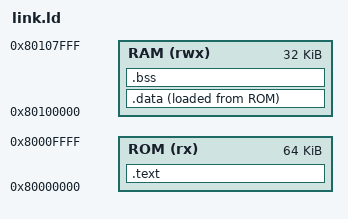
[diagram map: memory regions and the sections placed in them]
/* Memory map consumed by rtl/soc/rv32_nano_soc.sv. */
OUTPUT_ARCH(riscv)
ENTRY(_start)

MEMORY
{
    ROM (rx)  : ORIGIN = 0x80000000, LENGTH = 64K
    RAM (rwx) : ORIGIN = 0x80100000, LENGTH = 32K
}

/* _sp is the top of the dedicated machine-interrupt stack.  The software
 * stacks and .bss are placed below it by the linker. */
_sp = ORIGIN(RAM) + LENGTH(RAM);

SECTIONS
{
    .text : ALIGN(4)
    {
        KEEP(*(.text.startup))
        KEEP(*(.text.entry))
        *(.text .text.*)
        *(.rodata .rodata.*)
        . = ALIGN(4);
        __text_end = .;
    } > ROM

    .data : ALIGN(4)
    {
        __data_start = .;
        *(.data .data.*)
        . = ALIGN(4);
        __data_end = .;
    } > RAM AT > ROM
    __data_load = LOADADDR(.data);

    .bss (NOLOAD) : ALIGN(4)
    {
        __bss_start = .;
        *(.bss .bss.* COMMON)
        . = ALIGN(4);
        __bss_end = .;
    } > RAM

    . = ALIGN(4);
    __image_end = .;

    /DISCARD/ :
    {
        *(.comment)
        *(.note*)
        *(.eh_frame*)
        *(.riscv.attributes)
    }
}
